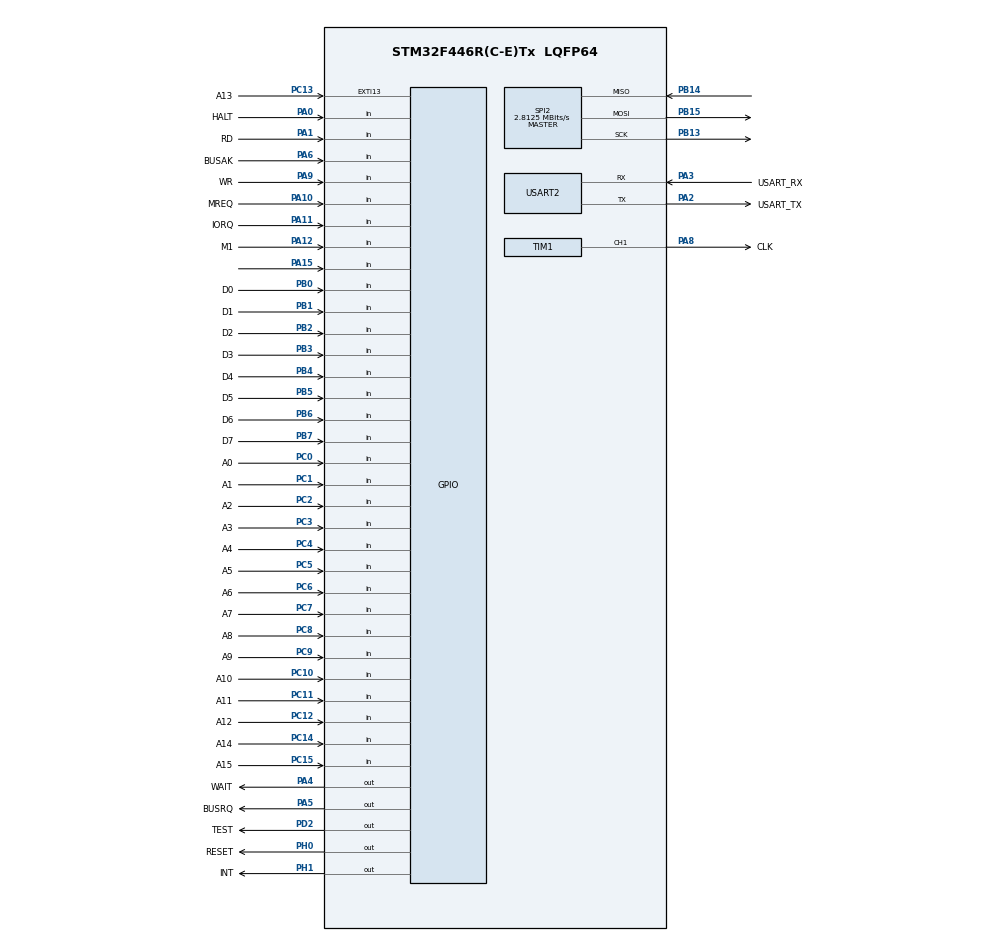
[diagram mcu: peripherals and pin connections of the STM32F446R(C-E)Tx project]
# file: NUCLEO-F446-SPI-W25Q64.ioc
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Mcu.Family=STM32F4
Mcu.Name=STM32F446R(C-E)Tx
Mcu.Package=LQFP64
NVIC.PriorityGroup=NVIC_PRIORITYGROUP_0
PA0-WKUP.GPIO_Label=HALT
PA0-WKUP.Signal=GPIO_Input
PA1.GPIO_Label=RD
PA1.GPIO_PuPd=GPIO_PULLUP
PA1.Signal=GPIO_Input
PA10.GPIO_Label=MREQ
PA10.GPIO_PuPd=GPIO_PULLUP
PA10.Signal=GPIO_Input
PA11.GPIO_Label=IORQ
PA11.GPIO_PuPd=GPIO_PULLUP
PA11.Signal=GPIO_Input
PA12.GPIO_Label=M1
PA12.GPIO_PuPd=GPIO_NOPULL
PA12.Signal=GPIO_Input
PA13.GPIO_Label=TMS
PA13.Mode=Serial_Wire
PA13.Signal=SYS_JTMS-SWDIO
PA14.GPIO_Label=TCK
PA14.Mode=Serial_Wire
PA14.Signal=SYS_JTCK-SWCLK
PA15.Signal=GPIO_Input
PA2.GPIO_Label=USART_TX
PA2.Mode=Asynchronous
PA2.Signal=USART2_TX
PA3.GPIO_Label=USART_RX
PA3.Mode=Asynchronous
PA3.Signal=USART2_RX
PA4.GPIO_Label=WAIT
PA4.GPIO_Speed=GPIO_SPEED_FREQ_VERY_HIGH
PA4.PinState=GPIO_PIN_SET
PA4.Signal=GPIO_Output
PA5.GPIO_Label=BUSRQ
PA5.GPIO_Speed=GPIO_SPEED_FREQ_VERY_HIGH
PA5.PinState=GPIO_PIN_SET
PA5.Signal=GPIO_Output
PA6.GPIO_Label=BUSAK
PA6.Signal=GPIO_Input
PA7.GPIO_Speed=GPIO_SPEED_FREQ_VERY_HIGH
PA7.Signal=TIM1_CH1N
PA8.GPIO_Label=CLK
PA8.GPIO_Speed=GPIO_SPEED_FREQ_VERY_HIGH
PA8.Signal=S_TIM1_CH1
PA9.GPIO_Label=WR
PA9.GPIO_PuPd=GPIO_PULLUP
PA9.Signal=GPIO_Input
PB0.GPIO_Label=D0
PB0.Signal=GPIO_Input
PB1.GPIO_Label=D1
PB1.Signal=GPIO_Input
PB12.Signal=SPI2_NSS
PB13.Mode=Full_Duplex_Master
PB13.Signal=SPI2_SCK
PB14.Mode=Full_Duplex_Master
PB14.Signal=SPI2_MISO
PB15.Mode=Full_Duplex_Master
PB15.Signal=SPI2_MOSI
PB2.GPIO_Label=D2
PB2.Signal=GPIO_Input
PB3.GPIO_Label=D3
PB3.Signal=GPIO_Input
PB4.GPIO_Label=D4
PB4.Signal=GPIO_Input
PB5.GPIO_Label=D5
PB5.Signal=GPIO_Input
PB6.GPIO_Label=D6
PB6.Signal=GPIO_Input
PB7.GPIO_Label=D7
PB7.Signal=GPIO_Input
PB8.Signal=I2C1_SCL
PB9.Signal=I2C1_SDA
PC0.GPIO_Label=A0
PC0.GPIO_PuPd=GPIO_PULLUP
PC0.Signal=GPIO_Input
PC1.GPIO_Label=A1
PC1.GPIO_PuPd=GPIO_PULLUP
PC1.Signal=GPIO_Input
PC10.GPIO_Label=A10
PC10.GPIO_PuPd=GPIO_PULLUP
PC10.Signal=GPIO_Input
PC11.GPIO_Label=A11
PC11.GPIO_PuPd=GPIO_PULLUP
PC11.Signal=GPIO_Input
PC12.GPIO_Label=A12
PC12.GPIO_PuPd=GPIO_PULLUP
PC12.Signal=GPIO_Input
PC13.GPIO_Label=A13
PC13.GPIO_ModeDefaultEXTI=GPIO_MODE_IT_FALLING
PC13.GPIO_PuPd=GPIO_PULLUP
PC13.Signal=GPXTI13
PC14-OSC32_IN.GPIO_Label=A14
PC14-OSC32_IN.GPIO_PuPd=GPIO_PULLUP
PC14-OSC32_IN.Signal=GPIO_Input
PC15-OSC32_OUT.GPIO_Label=A15
PC15-OSC32_OUT.GPIO_PuPd=GPIO_PULLUP
PC15-OSC32_OUT.Signal=GPIO_Input
PC2.GPIO_Label=A2
PC2.GPIO_PuPd=GPIO_PULLUP
PC2.Signal=GPIO_Input
PC3.GPIO_Label=A3
PC3.GPIO_PuPd=GPIO_PULLUP
PC3.Signal=GPIO_Input
PC4.GPIO_Label=A4
PC4.GPIO_PuPd=GPIO_PULLUP
PC4.Signal=GPIO_Input
PC5.GPIO_Label=A5
PC5.Signal=GPIO_Input
PC6.GPIO_Label=A6
PC6.GPIO_PuPd=GPIO_PULLUP
PC6.Signal=GPIO_Input
PC7.GPIO_Label=A7
PC7.GPIO_PuPd=GPIO_PULLUP
PC7.Signal=GPIO_Input
PC8.GPIO_Label=A8
PC8.GPIO_PuPd=GPIO_PULLUP
PC8.Signal=GPIO_Input
PC9.GPIO_Label=A9
PC9.GPIO_PuPd=GPIO_PULLUP
PC9.Signal=GPIO_Input
PD2.GPIO_Label=TEST
PD2.GPIO_Speed=GPIO_SPEED_FREQ_VERY_HIGH
PD2.Signal=GPIO_Output
PH0-OSC_IN.GPIO_Label=RESET
PH0-OSC_IN.GPIO_Speed=GPIO_SPEED_FREQ_VERY_HIGH
PH0-OSC_IN.Signal=GPIO_Output
PH1-OSC_OUT.GPIO_Label=INT
PH1-OSC_OUT.Signal=GPIO_Output
ProjectManager.HeapSize=0x200
ProjectManager.StackSize=0x400
ProjectManager.TargetToolchain=STM32CubeIDE
RCC.48MHZClocksFreq_Value=84000000
RCC.AHBFreq_Value=180000000
RCC.APB1CLKDivider=RCC_HCLK_DIV4
RCC.APB1Freq_Value=45000000
RCC.APB1TimFreq_Value=90000000
RCC.APB2CLKDivider=RCC_HCLK_DIV2
RCC.APB2Freq_Value=90000000
RCC.APB2TimFreq_Value=180000000
RCC.CortexFreq_Value=180000000
RCC.FLatency-AdvancedSettings=FLASH_LATENCY_5
RCC.HCLKFreq_Value=180000000
RCC.HSE_VALUE=8000000
RCC.HSI_VALUE=16000000
RCC.PLLN=360
RCC.SYSCLKFreq_VALUE=180000000
RCC.SYSCLKSource=RCC_SYSCLKSOURCE_PLLCLK
RCC.USBFreq_Value=180000000
RCC.VCOOutputFreq_Value=360000000
SH.S_TIM1_CH1.0=TIM1_CH1,Output Compare1 CH1
SPI2.BaudRatePrescaler=SPI_BAUDRATEPRESCALER_16
SPI2.CalculateBaudRate=2.8125 MBits/s
SPI2.Direction=SPI_DIRECTION_2LINES
SPI2.Mode=SPI_MODE_MASTER
SPI2.VirtualType=VM_MASTER
TIM1.Channel-Output\ Compare1\ CH1=TIM_CHANNEL_1
USART2.VirtualMode=VM_ASYNC
VP_TIM1_VS_ClockSourceINT.Mode=Internal
board=NUCLEO-F446RE

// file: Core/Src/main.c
/* USER CODE BEGIN Header */
/**
  ******************************************************************************
  * @file           : main.c
  * @brief          : Main program body
  ******************************************************************************
  * @attention
  *
  * <h2><center>&copy; Copyright (c) 2021 STMicroelectronics.
  * All rights reserved.</center></h2>
  *
  * This software component is licensed by ST under BSD 3-Clause license,
  * the "License"; You may not use this file except in compliance with the
  * License. You may obtain a copy of the License at:
  *                        opensource.org/licenses/BSD-3-Clause
  *
  ******************************************************************************
  */
/* USER CODE END Header */
#include "main.h"

/* USER CODE BEGIN Includes */
#include <stdio.h>
#include "monitor.h"
/* USER CODE END Includes */

SPI_HandleTypeDef hspi2;

/* USER CODE BEGIN PV */
uint8_t sram[65536];

/* USER CODE END PV */

void SystemClock_Config(void);
static void MX_GPIO_Init(void);
static void MX_USART2_UART_Init(void);
static void MX_TIM1_Init(void);
static void MX_SPI2_Init(void);

int main(void)
{

  /* MCU Configuration--------------------------------------------------------*/

  /* Reset of all peripherals, Initializes the Flash interface and the Systick. */
  HAL_Init();

  /* Configure the system clock */
  SystemClock_Config();

  /* Initialize all configured peripherals */
  MX_GPIO_Init();
  MX_USART2_UART_Init();
  MX_TIM1_Init();
  MX_SPI2_Init();
  /* USER CODE BEGIN 2 */
  setbuf (stdout, NULL);
  setbuf (stdin, NULL);

  /* USER CODE END 2 */

  /* Infinite loop */
  while (1)
  {

    /* USER CODE BEGIN 3 */
	  monitor (sram, NULL);
  }
  /* USER CODE END 3 */
}

void SystemClock_Config(void)
{
  LL_FLASH_SetLatency(LL_FLASH_LATENCY_5);
  while(LL_FLASH_GetLatency()!= LL_FLASH_LATENCY_5)
  {
  }
  LL_PWR_SetRegulVoltageScaling(LL_PWR_REGU_VOLTAGE_SCALE1);
  LL_PWR_EnableOverDriveMode();
  LL_RCC_HSI_SetCalibTrimming(16);
  LL_RCC_HSI_Enable();

   /* Wait till HSI is ready */
  while(LL_RCC_HSI_IsReady() != 1)
  {

  }
  LL_RCC_PLL_ConfigDomain_SYS(LL_RCC_PLLSOURCE_HSI, LL_RCC_PLLM_DIV_16, 360, LL_RCC_PLLP_DIV_2);
  LL_RCC_PLL_Enable();

   /* Wait till PLL is ready */
  while(LL_RCC_PLL_IsReady() != 1)
  {

  }
  LL_RCC_SetAHBPrescaler(LL_RCC_SYSCLK_DIV_1);
  LL_RCC_SetAPB1Prescaler(LL_RCC_APB1_DIV_4);
  LL_RCC_SetAPB2Prescaler(LL_RCC_APB2_DIV_2);
  LL_RCC_SetSysClkSource(LL_RCC_SYS_CLKSOURCE_PLL);

   /* Wait till System clock is ready */
  while(LL_RCC_GetSysClkSource() != LL_RCC_SYS_CLKSOURCE_STATUS_PLL)
  {

  }
  LL_SetSystemCoreClock(180000000);

   /* Update the time base */
  if (HAL_InitTick (TICK_INT_PRIORITY) != HAL_OK)
  {
    Error_Handler();
  }
  LL_RCC_SetTIMPrescaler(LL_RCC_TIM_PRESCALER_TWICE);
}

static void MX_SPI2_Init(void)
{

  /* SPI2 parameter configuration*/
  hspi2.Instance = SPI2;
  hspi2.Init.Mode = SPI_MODE_MASTER;
  hspi2.Init.Direction = SPI_DIRECTION_2LINES;
  hspi2.Init.DataSize = SPI_DATASIZE_8BIT;
  hspi2.Init.CLKPolarity = SPI_POLARITY_LOW;
  hspi2.Init.CLKPhase = SPI_PHASE_1EDGE;
  hspi2.Init.NSS = SPI_NSS_SOFT;
  hspi2.Init.BaudRatePrescaler = SPI_BAUDRATEPRESCALER_16;
  hspi2.Init.FirstBit = SPI_FIRSTBIT_MSB;
  hspi2.Init.TIMode = SPI_TIMODE_DISABLE;
  hspi2.Init.CRCCalculation = SPI_CRCCALCULATION_DISABLE;
  hspi2.Init.CRCPolynomial = 10;
  if (HAL_SPI_Init(&hspi2) != HAL_OK)
  {
    Error_Handler();
  }

}

static void MX_TIM1_Init(void)
{

  LL_TIM_InitTypeDef TIM_InitStruct = {0};
  LL_TIM_OC_InitTypeDef TIM_OC_InitStruct = {0};
  LL_TIM_BDTR_InitTypeDef TIM_BDTRInitStruct = {0};

  LL_GPIO_InitTypeDef GPIO_InitStruct = {0};

  /* Peripheral clock enable */
  LL_APB2_GRP1_EnableClock(LL_APB2_GRP1_PERIPH_TIM1);

  TIM_InitStruct.Prescaler = 0;
  TIM_InitStruct.CounterMode = LL_TIM_COUNTERMODE_UP;
  TIM_InitStruct.Autoreload = 65535;
  TIM_InitStruct.ClockDivision = LL_TIM_CLOCKDIVISION_DIV1;
  TIM_InitStruct.RepetitionCounter = 0;
  LL_TIM_Init(TIM1, &TIM_InitStruct);
  LL_TIM_DisableARRPreload(TIM1);
  LL_TIM_SetClockSource(TIM1, LL_TIM_CLOCKSOURCE_INTERNAL);
  TIM_OC_InitStruct.OCMode = LL_TIM_OCMODE_FROZEN;
  TIM_OC_InitStruct.OCState = LL_TIM_OCSTATE_DISABLE;
  TIM_OC_InitStruct.OCNState = LL_TIM_OCSTATE_DISABLE;
  TIM_OC_InitStruct.CompareValue = 0;
  TIM_OC_InitStruct.OCPolarity = LL_TIM_OCPOLARITY_HIGH;
  TIM_OC_InitStruct.OCNPolarity = LL_TIM_OCPOLARITY_HIGH;
  TIM_OC_InitStruct.OCIdleState = LL_TIM_OCIDLESTATE_LOW;
  TIM_OC_InitStruct.OCNIdleState = LL_TIM_OCIDLESTATE_LOW;
  LL_TIM_OC_Init(TIM1, LL_TIM_CHANNEL_CH1, &TIM_OC_InitStruct);
  LL_TIM_OC_DisableFast(TIM1, LL_TIM_CHANNEL_CH1);
  LL_TIM_SetTriggerOutput(TIM1, LL_TIM_TRGO_RESET);
  LL_TIM_DisableMasterSlaveMode(TIM1);
  TIM_BDTRInitStruct.OSSRState = LL_TIM_OSSR_DISABLE;
  TIM_BDTRInitStruct.OSSIState = LL_TIM_OSSI_DISABLE;
  TIM_BDTRInitStruct.LockLevel = LL_TIM_LOCKLEVEL_OFF;
  TIM_BDTRInitStruct.DeadTime = 0;
  TIM_BDTRInitStruct.BreakState = LL_TIM_BREAK_DISABLE;
  TIM_BDTRInitStruct.BreakPolarity = LL_TIM_BREAK_POLARITY_HIGH;
  TIM_BDTRInitStruct.AutomaticOutput = LL_TIM_AUTOMATICOUTPUT_DISABLE;
  LL_TIM_BDTR_Init(TIM1, &TIM_BDTRInitStruct);
  LL_AHB1_GRP1_EnableClock(LL_AHB1_GRP1_PERIPH_GPIOA);
  /**TIM1 GPIO Configuration
  PA7   ------> TIM1_CH1N
  PA8   ------> TIM1_CH1
  */
  GPIO_InitStruct.Pin = LL_GPIO_PIN_7|CLK_Pin;
  GPIO_InitStruct.Mode = LL_GPIO_MODE_ALTERNATE;
  GPIO_InitStruct.Speed = LL_GPIO_SPEED_FREQ_VERY_HIGH;
  GPIO_InitStruct.OutputType = LL_GPIO_OUTPUT_PUSHPULL;
  GPIO_InitStruct.Pull = LL_GPIO_PULL_NO;
  GPIO_InitStruct.Alternate = LL_GPIO_AF_1;
  LL_GPIO_Init(GPIOA, &GPIO_InitStruct);

}

static void MX_USART2_UART_Init(void)
{

  LL_USART_InitTypeDef USART_InitStruct = {0};

  LL_GPIO_InitTypeDef GPIO_InitStruct = {0};

  /* Peripheral clock enable */
  LL_APB1_GRP1_EnableClock(LL_APB1_GRP1_PERIPH_USART2);

  LL_AHB1_GRP1_EnableClock(LL_AHB1_GRP1_PERIPH_GPIOA);
  /**USART2 GPIO Configuration
  PA2   ------> USART2_TX
  PA3   ------> USART2_RX
  */
  GPIO_InitStruct.Pin = USART_TX_Pin|USART_RX_Pin;
  GPIO_InitStruct.Mode = LL_GPIO_MODE_ALTERNATE;
  GPIO_InitStruct.Speed = LL_GPIO_SPEED_FREQ_VERY_HIGH;
  GPIO_InitStruct.OutputType = LL_GPIO_OUTPUT_PUSHPULL;
  GPIO_InitStruct.Pull = LL_GPIO_PULL_NO;
  GPIO_InitStruct.Alternate = LL_GPIO_AF_7;
  LL_GPIO_Init(GPIOA, &GPIO_InitStruct);

  USART_InitStruct.BaudRate = 115200;
  USART_InitStruct.DataWidth = LL_USART_DATAWIDTH_8B;
  USART_InitStruct.StopBits = LL_USART_STOPBITS_1;
  USART_InitStruct.Parity = LL_USART_PARITY_NONE;
  USART_InitStruct.TransferDirection = LL_USART_DIRECTION_TX_RX;
  USART_InitStruct.HardwareFlowControl = LL_USART_HWCONTROL_NONE;
  USART_InitStruct.OverSampling = LL_USART_OVERSAMPLING_16;
  LL_USART_Init(USART2, &USART_InitStruct);
  LL_USART_ConfigAsyncMode(USART2);
  LL_USART_Enable(USART2);

}

static void MX_GPIO_Init(void)
{
  LL_EXTI_InitTypeDef EXTI_InitStruct = {0};
  LL_GPIO_InitTypeDef GPIO_InitStruct = {0};

  /* GPIO Ports Clock Enable */
  LL_AHB1_GRP1_EnableClock(LL_AHB1_GRP1_PERIPH_GPIOC);
  LL_AHB1_GRP1_EnableClock(LL_AHB1_GRP1_PERIPH_GPIOH);
  LL_AHB1_GRP1_EnableClock(LL_AHB1_GRP1_PERIPH_GPIOA);
  LL_AHB1_GRP1_EnableClock(LL_AHB1_GRP1_PERIPH_GPIOB);
  LL_AHB1_GRP1_EnableClock(LL_AHB1_GRP1_PERIPH_GPIOD);

  /**/
  LL_GPIO_ResetOutputPin(GPIOH, RESET_Pin|INT_Pin);

  /**/
  LL_GPIO_ResetOutputPin(TEST_GPIO_Port, TEST_Pin);

  /**/
  LL_GPIO_SetOutputPin(GPIOA, WAIT_Pin|BUSRQ_Pin);

  /**/
  LL_SYSCFG_SetEXTISource(LL_SYSCFG_EXTI_PORTC, LL_SYSCFG_EXTI_LINE13);

  /**/
  EXTI_InitStruct.Line_0_31 = LL_EXTI_LINE_13;
  EXTI_InitStruct.LineCommand = ENABLE;
  EXTI_InitStruct.Mode = LL_EXTI_MODE_IT;
  EXTI_InitStruct.Trigger = LL_EXTI_TRIGGER_FALLING;
  LL_EXTI_Init(&EXTI_InitStruct);

  /**/
  LL_GPIO_SetPinPull(A13_GPIO_Port, A13_Pin, LL_GPIO_PULL_UP);

  /**/
  LL_GPIO_SetPinMode(A13_GPIO_Port, A13_Pin, LL_GPIO_MODE_INPUT);

  /**/
  GPIO_InitStruct.Pin = A14_Pin|A15_Pin|A0_Pin|A1_Pin
                          |A2_Pin|A3_Pin|A4_Pin|A6_Pin
                          |A7_Pin|A8_Pin|A9_Pin|A10_Pin
                          |A11_Pin|A12_Pin;
  GPIO_InitStruct.Mode = LL_GPIO_MODE_INPUT;
  GPIO_InitStruct.Pull = LL_GPIO_PULL_UP;
  LL_GPIO_Init(GPIOC, &GPIO_InitStruct);

  /**/
  GPIO_InitStruct.Pin = RESET_Pin;
  GPIO_InitStruct.Mode = LL_GPIO_MODE_OUTPUT;
  GPIO_InitStruct.Speed = LL_GPIO_SPEED_FREQ_VERY_HIGH;
  GPIO_InitStruct.OutputType = LL_GPIO_OUTPUT_PUSHPULL;
  GPIO_InitStruct.Pull = LL_GPIO_PULL_NO;
  LL_GPIO_Init(RESET_GPIO_Port, &GPIO_InitStruct);

  /**/
  GPIO_InitStruct.Pin = INT_Pin;
  GPIO_InitStruct.Mode = LL_GPIO_MODE_OUTPUT;
  GPIO_InitStruct.Speed = LL_GPIO_SPEED_FREQ_LOW;
  GPIO_InitStruct.OutputType = LL_GPIO_OUTPUT_PUSHPULL;
  GPIO_InitStruct.Pull = LL_GPIO_PULL_NO;
  LL_GPIO_Init(INT_GPIO_Port, &GPIO_InitStruct);

  /**/
  GPIO_InitStruct.Pin = HALT_Pin|BUSAK_Pin|M1_Pin|LL_GPIO_PIN_15;
  GPIO_InitStruct.Mode = LL_GPIO_MODE_INPUT;
  GPIO_InitStruct.Pull = LL_GPIO_PULL_NO;
  LL_GPIO_Init(GPIOA, &GPIO_InitStruct);

  /**/
  GPIO_InitStruct.Pin = RD_Pin|WR_Pin|MREQ_Pin|IORQ_Pin;
  GPIO_InitStruct.Mode = LL_GPIO_MODE_INPUT;
  GPIO_InitStruct.Pull = LL_GPIO_PULL_UP;
  LL_GPIO_Init(GPIOA, &GPIO_InitStruct);

  /**/
  GPIO_InitStruct.Pin = WAIT_Pin|BUSRQ_Pin;
  GPIO_InitStruct.Mode = LL_GPIO_MODE_OUTPUT;
  GPIO_InitStruct.Speed = LL_GPIO_SPEED_FREQ_VERY_HIGH;
  GPIO_InitStruct.OutputType = LL_GPIO_OUTPUT_PUSHPULL;
  GPIO_InitStruct.Pull = LL_GPIO_PULL_NO;
  LL_GPIO_Init(GPIOA, &GPIO_InitStruct);

  /**/
  GPIO_InitStruct.Pin = A5_Pin;
  GPIO_InitStruct.Mode = LL_GPIO_MODE_INPUT;
  GPIO_InitStruct.Pull = LL_GPIO_PULL_NO;
  LL_GPIO_Init(A5_GPIO_Port, &GPIO_InitStruct);

  /**/
  GPIO_InitStruct.Pin = D0_Pin|D1_Pin|D2_Pin|D3_Pin
                          |D4_Pin|D5_Pin|D6_Pin|D7_Pin;
  GPIO_InitStruct.Mode = LL_GPIO_MODE_INPUT;
  GPIO_InitStruct.Pull = LL_GPIO_PULL_NO;
  LL_GPIO_Init(GPIOB, &GPIO_InitStruct);

  /**/
  GPIO_InitStruct.Pin = TEST_Pin;
  GPIO_InitStruct.Mode = LL_GPIO_MODE_OUTPUT;
  GPIO_InitStruct.Speed = LL_GPIO_SPEED_FREQ_VERY_HIGH;
  GPIO_InitStruct.OutputType = LL_GPIO_OUTPUT_PUSHPULL;
  GPIO_InitStruct.Pull = LL_GPIO_PULL_NO;
  LL_GPIO_Init(TEST_GPIO_Port, &GPIO_InitStruct);

  /**/
  GPIO_InitStruct.Pin = LL_GPIO_PIN_8|LL_GPIO_PIN_9;
  GPIO_InitStruct.Mode = LL_GPIO_MODE_ALTERNATE;
  GPIO_InitStruct.Speed = LL_GPIO_SPEED_FREQ_VERY_HIGH;
  GPIO_InitStruct.OutputType = LL_GPIO_OUTPUT_OPENDRAIN;
  GPIO_InitStruct.Pull = LL_GPIO_PULL_UP;
  GPIO_InitStruct.Alternate = LL_GPIO_AF_4;
  LL_GPIO_Init(GPIOB, &GPIO_InitStruct);

}

void Error_Handler(void)
{
}

/************************ (C) COPYRIGHT STMicroelectronics *****END OF FILE****/
